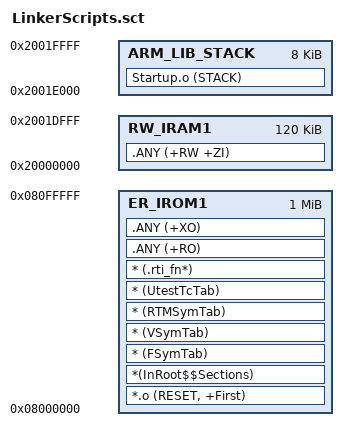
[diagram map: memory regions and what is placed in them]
; *************************************************************
; *** Scatter-Loading Description File generated by uVision ***
; *************************************************************

LR_IROM1 0x08000000 0x00100000  {    ; load region size_region
  ER_IROM1 0x08000000 0x00100000  {  ; load address = execution address
   *.o (RESET, +First)
   *(InRoot$$Sections)

   ; RT-Thread registration tables must stay contiguous and must be placed
   ; before .ANY. The linker generates SectionName$$Base/Limit symbols for
   ; FinSH, module and utest code to locate these tables at run time.
   * (FSymTab)
   * (VSymTab)
   * (RTMSymTab)
   * (UtestTcTab)
   * (.rti_fn*)

   .ANY (+RO)
   .ANY (+XO)
  }
  RW_IRAM1 0x20000000 0x0001E000  {  ; SRAM below the main stack
   .ANY (+RW +ZI)
  }
  ARM_LIB_STACK 0x2001E000 0x00002000  {  ; Reserve 8 KB at SRAM top
   Startup.o (STACK)
  }
}
